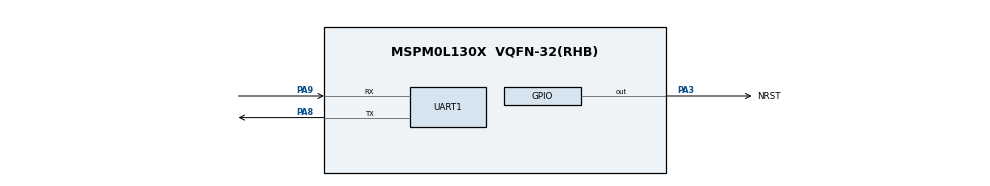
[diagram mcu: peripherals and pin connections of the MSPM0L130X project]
// @cliArgs --device "MSPM0L130X" --package "VQFN-32(RHB)" --part "Default"
// @cliArgs --board /ti/boards/LP_MSPM0L1306 --rtos nortos

/**
 * Import the modules used in this configuration.
 */
const GPIO  = scripting.addModule("/ti/driverlib/GPIO", {}, false);
const GPIO1 = GPIO.addInstance();
const GPIO2 = GPIO.addInstance();
const GPIO3 = GPIO.addInstance();
const UART  = scripting.addModule("/ti/driverlib/UART", {}, false);
const UART1 = UART.addInstance();

/**
 * Write custom configuration values to the imported modules.
 */
GPIO1.$name                              = "GPIO_Button";
GPIO1.associatedPins[0].$name            = "PIN_0";
GPIO1.associatedPins[0].assignedPort     = "PORTA";
GPIO1.associatedPins[0].assignedPin      = "14";
GPIO1.associatedPins[0].direction        = "INPUT";
GPIO1.associatedPins[0].internalResistor = "PULL_UP";

const Board           = scripting.addModule("/ti/driverlib/Board", {}, false);
Board.configureUnused = true;

GPIO2.$name                          = "GPIO_BSL";
GPIO2.associatedPins.create(2);
GPIO2.associatedPins[0].$name        = "NRST";
GPIO2.associatedPins[0].assignedPort = "PORTA";
GPIO2.associatedPins[0].assignedPin  = "3";
GPIO2.associatedPins[0].pin.$assign  = "PA3";
GPIO2.associatedPins[1].$name        = "Invoke";
GPIO2.associatedPins[1].assignedPort = "PORTA";
GPIO2.associatedPins[1].assignedPin  = "7";

GPIO3.$name                          = "GPIO_LED";
GPIO3.associatedPins.create(2);
GPIO3.associatedPins[0].$name        = "PA0";
GPIO3.associatedPins[1].assignedPort = "PORTA";
GPIO3.associatedPins[1].assignedPin  = "27";
GPIO3.associatedPins[1].$name        = "Error";

const SYSCTL       = scripting.addModule("/ti/driverlib/SYSCTL", {}, false);
SYSCTL.powerPolicy = "STANDBY0";
SYSCTL.clockTreeEn = true;

UART1.$name                    = "UART_0";
UART1.rxFifoThreshold          = "DL_UART_RX_FIFO_LEVEL_ONE_ENTRY";
UART1.enableDMARX              = false;
UART1.enableDMATX              = false;
UART1.enabledInterrupts        = ["RX"];
UART1.peripheral.$assign       = "UART0";
UART1.peripheral.rxPin.$assign = "PA9";
UART1.peripheral.txPin.$assign = "PA8";
